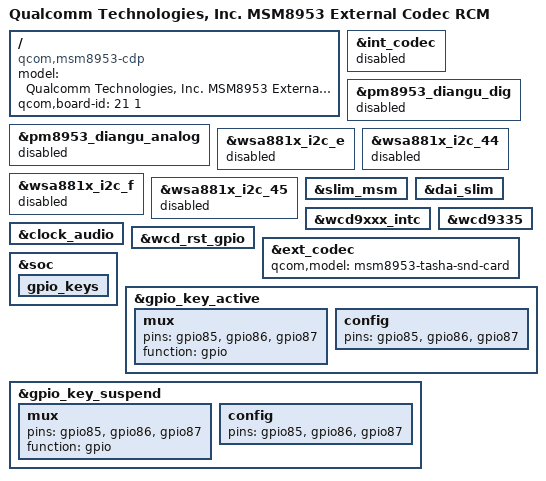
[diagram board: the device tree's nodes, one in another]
/*
 * Copyright (c) 2015-2016, The Linux Foundation. All rights reserved.
 * Copyright (C) 2017 XiaoMi, Inc.
 *
 * This program is free software; you can redistribute it and/or modify
 * it under the terms of the GNU General Public License version 2 and
 * only version 2 as published by the Free Software Foundation.
 *
 * This program is distributed in the hope that it will be useful,
 * but WITHOUT ANY WARRANTY; without even the implied warranty of
 * MERCHANTABILITY or FITNESS FOR A PARTICULAR PURPOSE.  See the
 * GNU General Public License for more details.
 */

/dts-v1/;

#include "msm8953.dtsi"
#include "msm8953-cdp.dtsi"

/ {
	model = "Qualcomm Technologies, Inc. MSM8953 External Codec RCM";
	compatible = "qcom,msm8953-cdp", "qcom,msm8953", "qcom,cdp";
	qcom,board-id= <21 1>;
};

&int_codec {
	status = "disabled";
};

&pm8953_diangu_dig {
	status = "disabled";
};

&pm8953_diangu_analog {
	status = "disabled";
};

&wsa881x_i2c_e {
	status = "disabled";
};

&wsa881x_i2c_44 {
	status = "disabled";
};

&wsa881x_i2c_f {
	status = "disabled";
};

&wsa881x_i2c_45 {
	status = "disabled";
};

&slim_msm {
	status = "okay";
};

&dai_slim {
	status = "okay";
};

&wcd9xxx_intc {
	status = "okay";
};

&clock_audio {
	status = "okay";
};

&wcd9335 {
	status = "okay";
};

&wcd_rst_gpio {
	status = "okay";
};

&ext_codec {
	qcom,model = "msm8953-tasha-snd-card";
	status = "okay";
};

&soc {
	gpio_keys {
		/delete-node/ home;
	};
};

&gpio_key_active {
	mux {
		pins = "gpio85", "gpio86", "gpio87";
		function = "gpio";
	};

	config {
		pins = "gpio85", "gpio86", "gpio87";
	};
};

&gpio_key_suspend {
	mux {
		pins = "gpio85", "gpio86", "gpio87";
		function = "gpio";
	};

	config {
		pins = "gpio85", "gpio86", "gpio87";
	};
};
